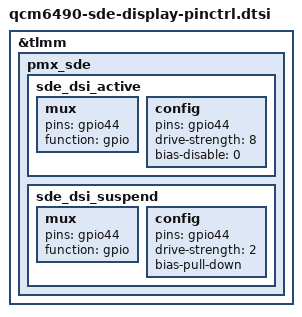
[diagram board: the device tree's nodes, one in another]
// SPDX-License-Identifier: BSD-3-Clause
/*
 * Copyright (c) 2023 Qualcomm Innovation Center, Inc. All rights reserved.
 */

&tlmm {
	pmx_sde: pmx_sde {
		sde_dsi_active: sde_dsi_active {
			mux {
				pins = "gpio44";
				function = "gpio";
			};

			config {
				pins = "gpio44";
				drive-strength = <8>;   /* 8 mA */
				bias-disable = <0>;     /* no pull */
			};
		};

		sde_dsi_suspend: sde_dsi_suspend {
			mux {
				pins = "gpio44";
				function = "gpio";
			};

			config {
				pins = "gpio44";
				drive-strength = <2>;   /* 2 mA */
				bias-pull-down;         /* PULL DOWN */
			};
		};
	};
};
